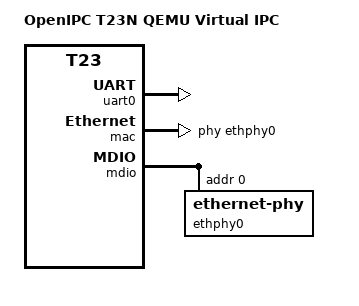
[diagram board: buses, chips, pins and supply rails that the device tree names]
// SPDX-License-Identifier: GPL-2.0
// Copyright (C) 2026 Difan Zhang

#include "ja-a12.dts"

/ {
	model = "OpenIPC T23N QEMU Virtual IPC";
	compatible = "openipc,t23-qemu", "jooan,ja-a12", "ingenic,t23";
};

&uart0 {
	pinctrl-names = "default";
	pinctrl-0 = <&pins_uart0_b>;
	status = "okay";
};

&mac {
	phy-handle = <&ethphy0>;
	status = "okay";
};

&mdio {
	status = "okay";

	ethphy0: ethernet-phy@0 {
		reg = <0>;
	};
};
